# apollo4p register map
Vendor: Ambiq Micro; Series: Apollo; File version: 1.0
CPU: CM4 r1p0, little endian, MPU, FPU, I-cache, D-cache, VTOR, ITCM, DTCM, 3 interrupt priority bits, 0 interrupts
Registers are 32-bit, read-write, reset 0x0 unless marked. A register's access mark holds for its fields unless they carry their own. Offsets are from the block's base; [hi:lo] are bit positions; {n}, {i} and the like mark numbered series.

## APBDMA — APB DMA Register Interfaces
Base 0x40011000
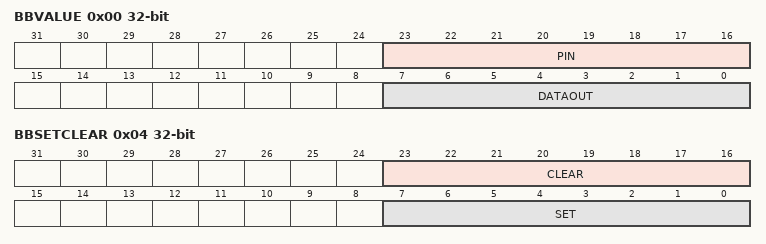
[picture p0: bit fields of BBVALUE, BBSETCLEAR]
0x00 BBVALUE — Control
  [23:16] PIN — PIO values
  [7:0] DATAOUT — Data Output Values
0x04 BBSETCLEAR — Set/Clear
  [23:16] CLEAR — Write 1 to Clear PIO value
  [7:0] SET — Write 1 to Set PIO value (set hier priority than clear if both bit set)
0x08 BBINPUT — PIO Input Values
  [7:0] DATAIN — PIO values
0x20 DEBUGDATA — PIO Input Values
0x40 DEBUG — PIO Input Values
  [3:0] DEBUGEN — Debug Enable
    0=OFF (Debug Disabled); 1=ARB (Debug Arb values)

## FPIO — Fast PIO access
Base 0x48001000
{0x0+4i} RD{i} (i=0..3) — GPIO Input {i} ({32i+31}-{32i})
  [31:0] RD{i} — GPIO{32i+31}-{32i} Reads pin state - read only. Returns the pad pin state for pins 0-31 if the PINCFG's input enable (INPEN) is active and RDZERO is inactive.
{0x10+4i} WT{i} (i=0..3) — GPIO Output {i} ({32i+31}-{32i})
  [31:0] WT{i} — GPIO{32i+31}-{32i} Reads or writes pin state. Writes of 1 bits set output pad signal if the GPIO is enabled for output. Reads return status, including sets/clears through the WTS and WTC registers.
{0x20+4i} WTS{i} (i=0..3) — GPIO Output Set {i} ({32i+31}-{32i})
  [31:0] WTS{i} — GPIO{32i+31}-{32i} Sets pin state. Writing a 1 to any bit sets the corresponding bit in the WT register if the GPIO is enabled for output. Writing a value of 0 has no effect on the corresponding bit in the WT register. Status reads should be made via the WT Register.
{0x30+4i} WTC{i} (i=0..3) — GPIO Output Clear {i} ({32i+31}-{32i})
  [31:0] WTC{i} — GPIO{32i+31}-{32i} Clears pin state. Writing a 1 to any bit clears the corresponding bit in the WT register if the GPIO is enabled for output. Writing a value of 0 has no effect on the corresponding bit in the WT register. Status reads should be made via the WT register.
{0x40+4i} EN{i} (i=0..3) — GPIO Enable {i} ({32i+31}-{32i})
  [31:0] EN{i} — GPIO{32i+31}-{32i} Enables tri-state pin output. Writing a 1 to any bit enables, and writing a 0 to any bit disables, the output for the corresponding GPIO. Reads return output enable/disable status of GPIO.
{0x50+4i} ENS{i} (i=0..3) — GPIO Enable Set {i} ({32i+31}-{32i})
  [31:0] ENS{i} — GPIO{32i+31}-{32i} Sets pin tri-state output enables. Writing a 1 to any bit sets the corresponding bit in the EN register. Writing a value of 0 has no effect on the corresponding bit in the EN register. Status reads should be made to the EN Register.
{0x60+4i} ENC{i} (i=0..3) — GPIO Enable Clear {i} ({32i+31}-{32i})
  [31:0] ENC{i} — GPIO{32i+31}-{32i} Clears pin tri-state output enables. Writing a 1 to any bit clears the corresponding bit in the EN register. Writing a value of 0 has no effect on the corresponding bit in the EN register. Status reads should be made to the EN Register.

## RTC — Real Time Clock
Base 0x40004800
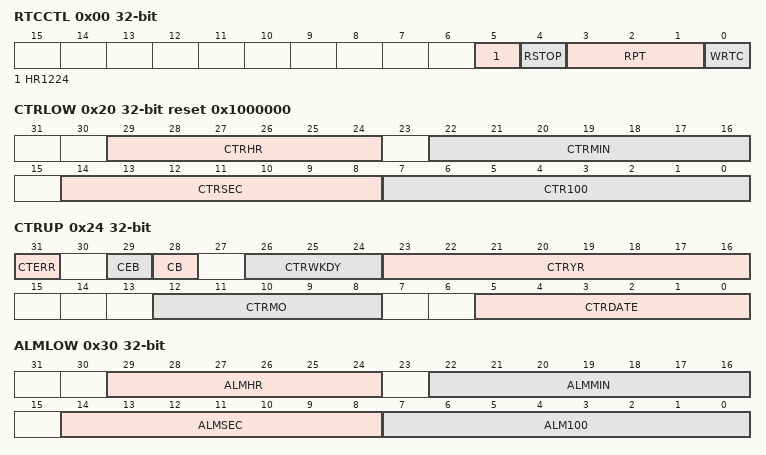
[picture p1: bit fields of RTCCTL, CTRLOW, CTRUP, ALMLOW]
0x00 RTCCTL — This is the register control for the RTC module. It enables counter writes and sets the alarm repeat interval.
  [5] HR1224 — Hours Counter mode Only 24HR mode supported
    0=24HR (Hours in 24 hour mode); 1=DISABLED (Disable the 24 hour mode)
  [4] RSTOP — RTC input clock control
    0=RUN (Allow the RTC input clock to run); 1=STOP (Stop the RTC input clock)
  [3:1] RPT — Alarm repeat interval
    0=DIS (Alarm interrupt disabled); 1=YEAR (Interrupt every year); 2=MONTH (Interrupt every month); 3=WEEK (Interrupt every week); 4=DAY (Interrupt every day); 5=HR (Interrupt every hour); 6=MIN (Interrupt every minute); 7=SEC (Interrupt every second/10th/100th)
  [0] WRTC — Counter write control
    0=DIS (Counter writes are disabled); 1=EN (Counter writes are enabled)
0x04 RTCSTAT — This is the register status for the RTC module.
  [0] WRITEBUSY — Indicates that an RTC update (write) is still in progress. Writes are initiated by writing the CTTLOW register - CTRUP must be written before CTRLOW to be updated (otherwise it will retain its current value)
0x20 CTRLOW reset 0x1000000 — This counter contains the values for hour, minutes, seconds and 100ths of a second Counter.
  [29:24] CTRHR — Hours Counter
  [22:16] CTRMIN — Minutes Counter
  [14:8] CTRSEC — Seconds Counter
  [7:0] CTR100 — 100ths of a second Counter
0x24 CTRUP — This register contains the day, month and year information. It contains which day in the week, and the century as well. The information of the century can also be derived from the year information. The 31st bit contains the error bit. See description in the register bit for condition when error is triggered.
  [31] CTERR — Counter read error status. Error is triggered when software reads the lower word of the counters, and fails to read the upper counter within 1/100 second. This is because when the lower counter is read, the upper counter is held off from incrementing until it is read so that the full time stamp can be read.
    0=NOERR (No read error occurred); 1=RDERR (Read error occurred)
  [29] CEB — Century enable
    0=DIS (Disable the Century bit from changing); 1=EN (Enable the Century bit to change)
  [28] CB — Century
    0=Century is 2000s; 1=1900_2100 (Century is 1900s/2100s)
  [26:24] CTRWKDY — Weekdays Counter
  [23:16] CTRYR — Years Counter
  [12:8] CTRMO — Months Counter
  [5:0] CTRDATE — Date Counter
0x30 ALMLOW — This register is the Alarm settings for hours, minutes, second and 1/100th seconds settings.
  [29:24] ALMHR — Hours Alarm
  [22:16] ALMMIN — Minutes Alarm
  [14:8] ALMSEC — Seconds Alarm
  [7:0] ALM100 — 100ths of a second Alarm
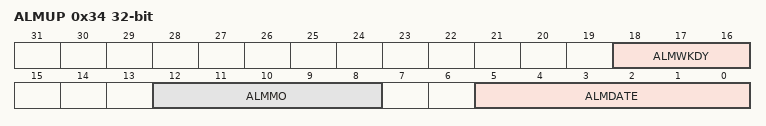
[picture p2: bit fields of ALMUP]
0x34 ALMUP — This register is the alarm settings for week, month and day.
  [18:16] ALMWKDY — Weekdays Alarm
  [12:8] ALMMO — Months Alarm
  [5:0] ALMDATE — Date Alarm
0x200 INTEN — Set bits in this register to allow this module to generate the corresponding interrupt.
  [0] ALM — RTC Alarm interrupt
0x204 INTSTAT — Read bits from this register to discover the cause of a recent interrupt.
  [0] ALM — RTC Alarm interrupt
0x208 INTCLR — Write a 1 to a bit in this register to clear the interrupt status associated with that bit.
  [0] ALM — RTC Alarm interrupt
0x20C INTSET — Write a 1 to a bit in this register to instantly generate an interrupt from this module. (Generally used for testing purposes).
  [0] ALM — RTC Alarm interrupt
